# MKE14Z4 register map
Vendor: nxp.com; File version: 1.0
CPU: CM0PLUS r0p0, little endian, no MPU, no FPU, VTOR, 2 interrupt priority bits
Registers are 32-bit, read-write, reset 0x0 unless marked. A register's access mark holds for its fields unless they carry their own. Offsets are from the block's base; [hi:lo] are bit positions.

## MCM — Core Platform Miscellaneous Control Module
Base 0xF0003000; register names take the prefix MCM_
0x08 PLASC 16-bit ro reset 0x7 — Crossbar Switch (AXBS) Slave Configuration
  [7:0] ASC — Each bit in the ASC field indicates whether there is a corresponding connection to the crossbar switch's slave input port.
    0=A bus slave connection to AXBS input port n is absent; 1=A bus slave connection to AXBS input port n is present
0x0A PLAMC 16-bit ro reset 0x5 — Crossbar Switch (AXBS) Master Configuration
  [7:0] AMC — Each bit in the AMC field indicates whether there is a corresponding connection to the AXBS master input port.
    0=A bus master connection to AXBS input port n is absent; 1=A bus master connection to AXBS input port n is present
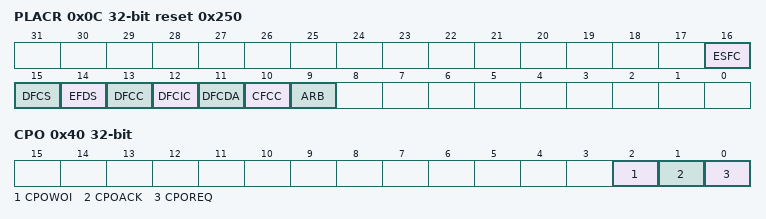
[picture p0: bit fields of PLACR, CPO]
0x0C PLACR reset 0x250 — Platform Control Register
  [16] ESFC — Enable Stalling Flash Controller
    0=Disable stalling flash controller when flash is busy; 1=Enable stalling flash controller when flash is busy
  [15] DFCS — Disable Flash Controller Speculation
    0=Enable flash controller speculation; 1=Disable flash controller speculation
  [14] EFDS — Enable Flash Data Speculation
    0=Disable flash data speculation; 1=Enable flash data speculation
  [13] DFCC — Disable Flash Controller Cache
    0=Enable flash controller cache; 1=Disable flash controller cache
  [12] DFCIC — Disable Flash Controller Instruction Caching
    0=Enable flash controller instruction caching; 1=Disable flash controller instruction caching
  [11] DFCDA — Disable Flash Controller Data Caching
    0=Enable flash controller data caching; 1=Disable flash controller data caching
  [10] CFCC — Clear Flash Controller Cache
  [9] ARB — Arbitration select
    0=Fixed-priority arbitration for the crossbar masters; 1=Round-robin arbitration for the crossbar masters
0x40 CPO — Compute Operation Control Register
  [2] CPOWOI — Compute Operation Wake-up on Interrupt
    0=No effect; 1=When set, the CPOREQ is cleared on any interrupt or exception vector fetch
  [1] CPOACK ro — Compute Operation Acknowledge
    0=Compute operation entry has not completed or compute operation exit has completed; 1=Compute operation entry has completed or compute operation exit has not completed
  [0] CPOREQ — Compute Operation Request
    0=Request is cleared; 1=Request Compute Operation

## MMDVSQ — Divide and Square Root
Base 0xF0004000; register names take the prefix MMDVSQ_
0x00 DEND reset not defined — Dividend Register
  [31:0] DIVIDEND
0x04 DSOR reset not defined — Divisor Register
  [31:0] DIVISOR
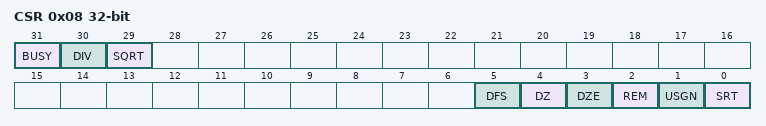
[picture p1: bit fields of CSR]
0x08 CSR (reset mask 0x9FFFFFFF) — Control/Status Register
  [31] BUSY ro
    0=MMDVSQ is idle; 1=MMDVSQ is busy performing a divide or square root calculation
  [30] DIV ro — DIVIDE
    0=Current or last MMDVSQ operation was not a divide; 1=Current or last MMDVSQ operation was a divide
  [29] SQRT ro — SQUARE ROOT
    0=Current or last MMDVSQ operation was not a square root; 1=Current or last MMDVSQ operation was a square root
  [5] DFS — Disable Fast Start
    0=A divide operation is initiated by a write to the DSOR register; 1=A divide operation is initiated by a write to the CSR register with CSR[SRT] = 1
  [4] DZ ro — Divide-by-Zero
    0=The last divide operation had a non-zero divisor, that is, DSOR != 0; 1=The last divide operation had a zero divisor, that is, DSOR = 0
  [3] DZE — Divide-by-Zero-Enable
    0=Reads of the RES register return the register contents; 1=If CSR[DZ] = 1, an attempted read of RES register is error terminated to signal a divide-by-zero, else the register contents are returned
  [2] REM — REMainder calculation
    0=Return the quotient in the RES for the divide calculation; 1=Return the remainder in the RES for the divide calculation
  [1] USGN — Unsigned calculation
    0=Perform a signed divide; 1=Perform an unsigned divide
  [0] SRT — Start
    0=No operation initiated; 1=If CSR[DFS] = 1, then initiate a divide calculation, else ignore
0x0C RES reset not defined — Result Register
  [31:0] RESULT
0x10 RCND wo reset not defined — Radicand Register
  [31:0] RADICAND

## FGPIOA — General Purpose Input/Output
Base 0xF8000000; register names take the prefix FGPIOA_
0x00 PDOR — Port Data Output Register
  [31:0] PDO — Port Data Output
    0=Logic level 0 is driven on pin, provided pin is configured for general-purpose output; 1=Logic level 1 is driven on pin, provided pin is configured for general-purpose output
0x04 PSOR — Port Set Output Register
  [31:0] PTSO — Port Set Output
    0=Corresponding bit in PDORn does not change; 1=Corresponding bit in PDORn is set to logic 1
0x08 PCOR — Port Clear Output Register
  [31:0] PTCO — Port Clear Output
    0=Corresponding bit in PDORn does not change; 1=Corresponding bit in PDORn is cleared to logic 0
0x0C PTOR — Port Toggle Output Register
  [31:0] PTTO — Port Toggle Output
    0=Corresponding bit in PDORn does not change; 1=Corresponding bit in PDORn is set to the inverse of its existing logic state
0x10 PDIR ro — Port Data Input Register
  [31:0] PDI — Port Data Input
    0=Pin logic level is logic 0, or is not configured for use by digital function; 1=Pin logic level is logic 1
0x14 PDDR — Port Data Direction Register
  [31:0] PDD — Port Data Direction
    0=Pin is configured as general-purpose input, for the GPIO function; 1=Pin is configured as general-purpose output, for the GPIO function

## FGPIOB — General Purpose Input/Output
Base 0xF8000040; register names take the prefix FGPIOB_
Registers as FGPIOA.

## FGPIOC — General Purpose Input/Output
Base 0xF8000080; register names take the prefix FGPIOC_
Registers as FGPIOA.

## FGPIOD — General Purpose Input/Output
Base 0xF80000C0; register names take the prefix FGPIOD_
Registers as FGPIOA.

## FGPIOE — General Purpose Input/Output
Base 0xF8000100; register names take the prefix FGPIOE_
Registers as FGPIOA.
